# STM32L152 register map
File version: 1.2
CPU: CM3 r1p1, little endian, no MPU, no FPU, 4 interrupt priority bits
Registers are 32-bit, read-write, reset 0x0 unless marked. A register's access mark holds for its fields unless they carry their own. Offsets are from the block's base; [hi:lo] are bit positions; {n}, {i} and the like mark numbered series.

## RI — Routing interface
Base 0x40007C04
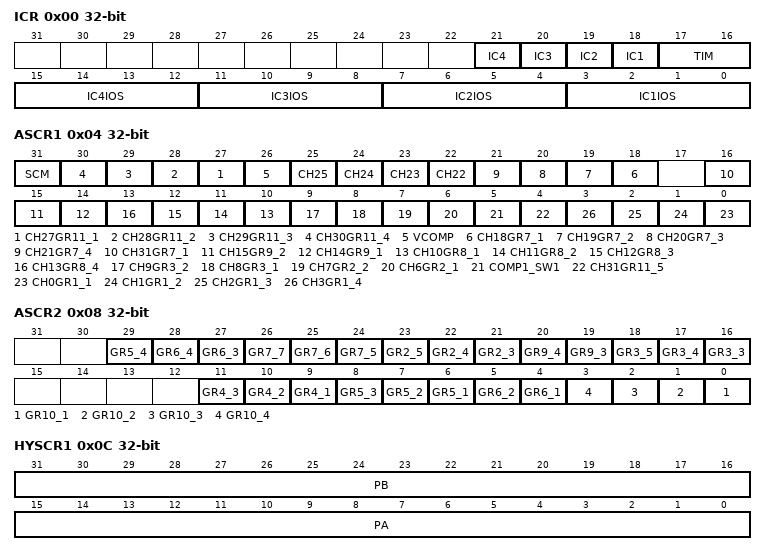
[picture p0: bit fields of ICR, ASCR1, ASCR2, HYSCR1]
0x00 ICR — RI input capture register
  [n+17] IC{n} (n=1..4)
  [17:16] TIM — Timer select bits
  [4n-1:4n-4] IC{n}IOS (n=1..4) — Input capture {n} select bits
0x04 ASCR1 — RI analog switches control register 1
  [31] SCM — Switch control mode
  [n] CH{n}GR11_{n-26} (n=27..30) — Analog switch control
  [26] VCOMP — ADC analog switch selection for internal node to comparator 1
  [n] CH{n} (n=22..25) — Analog I/O switch control of channel CH{n}
  [n] CH{n}GR7_{n-17} (n=18..21) — Analog switch control
  [16] CH31GR7_1 — Analog switch control
  [15] CH15GR9_2 — Analog switch control
  [14] CH14GR9_1 — Analog switch control
  [n] CH{n}GR8_{n-9} (n=10..13) — Analog switch control
  [9] CH9GR3_2 — Analog switch control
  [8] CH8GR3_1 — Analog switch control
  [7] CH7GR2_2 — Analog switch control
  [6] CH6GR2_1 — Analog switch control
  [5] COMP1_SW1 — Comparator 1 analog switch
  [4] CH31GR11_5 — Analog switch control
  [n] CH{n}GR1_{n+1} (n=0..3) — Analog switch control
0x08 ASCR2 — RI analog switches control register 2
  [29] GR5_4 — GR5_4 analog switch control
  [28] GR6_4 — GR6_4 analog switch control
  [27] GR6_3 — GR6_3 analog switch control
  [26] GR7_7 — GR7_7 analog switch control
  [25] GR7_6 — GR7_6 analog switch control
  [24] GR7_5 — GR7_5 analog switch control
  [23] GR2_5 — GR2_5 analog switch control
  [22] GR2_4 — GR2_4 analog switch control
  [21] GR2_3 — GR2_3 analog switch control
  [20] GR9_4 — GR9_4 analog switch control
  [19] GR9_3 — GR9_3 analog switch control
  [18] GR3_5 — GR3_5 analog switch control
  [17] GR3_4 — GR3_4 analog switch control
  [16] GR3_3 — GR3_3 analog switch control
  [11] GR4_3 — GR4_3 analog switch control
  [10] GR4_2 — GR4_2 analog switch control
  [9] GR4_1 — GR4_1 analog switch control
  [8] GR5_3 — GR5_3 analog switch control
  [7] GR5_2 — GR5_2 analog switch control
  [6] GR5_1 — GR5_1 analog switch control
  [5] GR6_2 — GR6_2 analog switch control
  [4] GR6_1 — GR6_1 analog switch control
  [n-1] GR10_{n} (n=1..4) — GR10_{n} analog switch control
0x0C HYSCR1 — RI hysteresis control register 1
  [31:16] PB — Port B hysteresis control on/off
  [15:0] PA — Port A hysteresis control on/off
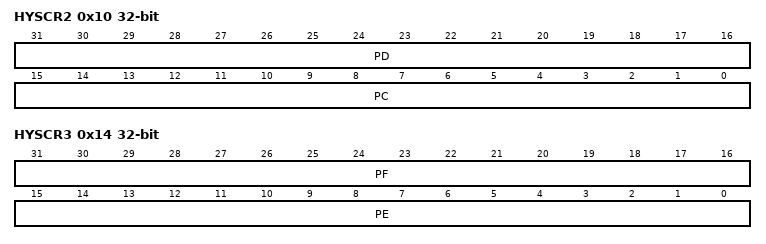
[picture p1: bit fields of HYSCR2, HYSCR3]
0x10 HYSCR2 — RI hysteresis control register 2
  [31:16] PD — Port D hysteresis control on/off
  [15:0] PC — Port C hysteresis control on/off
0x14 HYSCR3 — RI hysteresis control register 3
  [31:16] PF — Port F hysteresis control on/off
  [15:0] PE — Port E hysteresis control on/off
0x18 HYSCR4 — Hysteresis control register
  [15:0] PG — Port G hysteresis control on/off
0x1C ASMR1 — Analog switch mode register
  [15:0] PA — Port A analog switch mode selection
0x20 CMR1 — Channel mask register
  [15:0] PA — Port A channel masking
0x24 CICR1 — Channel identification for capture register
  [15:0] PA — Port A channel identification for capture
0x28 ASMR2 — Analog switch mode register
  [15:0] PB — Port B analog switch mode selection
0x2C CMR2 — Channel mask register
  [15:0] PB — Port B channel masking
0x30 CICR2 — Channel identification for capture register
  [15:0] PB — Port B channel identification for capture
0x34 ASMR3 — Analog switch mode register
  [15:0] PC — Port C analog switch mode selection
0x38 CMR3 — Channel mask register
  [15:0] PC — Port C channel masking
0x3C CICR3 — Channel identification for capture register
  [15:0] PC — Port C channel identification for capture
0x40 ASMR4 — Analog switch mode register
  [15:0] PF — Port F analog switch mode selection
0x44 CMR4 — Channel mask register
  [15:0] PF — Port F channel masking
0x48 CICR4 — Channel identification for capture register
  [15:0] PF — Port F channel identification for capture
0x4C ASMR5 — Analog switch mode register
  [15:0] PG — Port G analog switch mode selection
0x50 CMR5 — Channel mask register
  [15:0] PG — Port G channel masking
0x54 CICR5 — Channel identification for capture register
  [15:0] PG — Port G channel identification for capture
